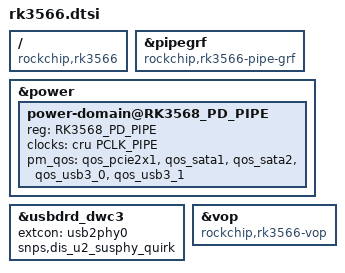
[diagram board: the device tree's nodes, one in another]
// SPDX-License-Identifier: (GPL-2.0+ OR MIT)

#include "rk356x.dtsi"

/ {
	compatible = "rockchip,rk3566";
};

&pipegrf {
	compatible = "rockchip,rk3566-pipe-grf", "syscon";
};

&power {
	power-domain@RK3568_PD_PIPE {
		reg = <RK3568_PD_PIPE>;
		clocks = <&cru PCLK_PIPE>;
		pm_qos = <&qos_pcie2x1>,
			 <&qos_sata1>,
			 <&qos_sata2>,
			 <&qos_usb3_0>,
			 <&qos_usb3_1>;
		#power-domain-cells = <0>;
	};
};

&usbdrd_dwc3 {
	extcon = <&usb2phy0>;
	snps,dis_u2_susphy_quirk;
};

&vop {
	compatible = "rockchip,rk3566-vop";
};
